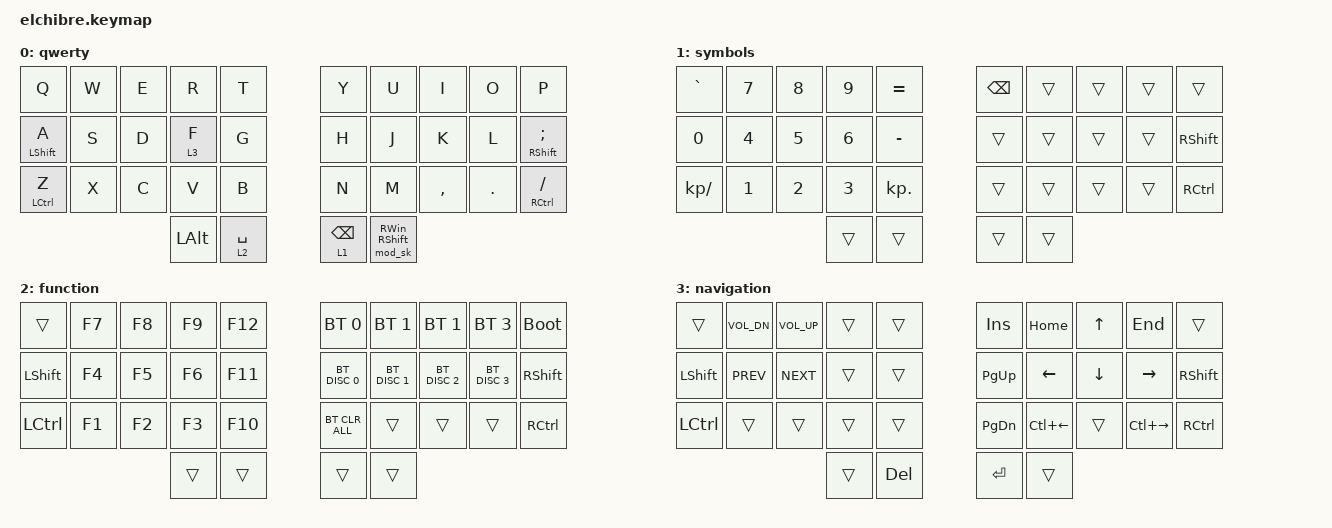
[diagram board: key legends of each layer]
#include <behaviors.dtsi>
#include <dt-bindings/zmk/bt.h>
#include <dt-bindings/zmk/keys.h>
#include <dt-bindings/zmk/outputs.h>
#include "zmk-helpers/helper.h"
#include "zmk-helpers/key-labels/34.h"
#include "behaviors.dtsi"
#include "combos.dtsi"



/ {
    keymap {
        compatible = "zmk,keymap";

        qwerty {
            bindings = <
                &kp  Q        &kp W  &kp E  &kp R    &kp T     &kp Y &kp U &kp I     &kp O      &kp P
                &hml LSHIFT A &kp S  &kp D  &lt 3 F  &kp G     &kp H &kp J &kp K     &kp L      &hmr RSHIFT SEMI
                &hml LCTRL Z  &kp X  &kp C  &kp V    &kp B     &kp N &kp M &kp COMMA &kp PERIOD &hmr RCTRL SLASH
                             &kp LALT         &lt 2 SPACE     &lt 1 BACKSPACE       &mod_sk RWIN RSHIFT 
            >;
        };

        symbols {
            bindings = <
                &kp GRAVE     &kp N7 &kp N8 &kp N9 &kp EQUAL       &kp BACKSPACE &trans &trans &trans &trans  
                &kp N0        &kp N4 &kp N5 &kp N6 &kp MINUS       &trans        &trans &trans &trans &kp RSHIFT
                &kp KP_SLASH  &kp N1 &kp N2 &kp N3 &kp KP_DOT      &trans        &trans &trans &trans &kp RCTRL
                                       &trans          &trans      &trans   &trans
            >;
        };

        function {
            bindings = <
                &trans    &kp F7 &kp F8 &kp F9 &kp F12          &bt BT_SEL 0  &bt BT_SEL 1  &bt BT_SEL 1  &bt BT_SEL 3   &bootloader
		&kp LSHFT &kp F4 &kp F5 &kp F6 &kp F11          &bt BT_DISC 0 &bt BT_DISC 1 &bt BT_DISC 2 &bt BT_DISC 3  &kp RSHIFT
                &kp LCTRL &kp F1 &kp F2 &kp F3 &kp F10          &bt BT_CLR_ALL&trans &trans &trans &kp RCTRL
                              &trans         &trans             &trans         &trans
            >;
        };

        navigation {
            bindings = <
                &trans    &kp C_VOL_DN &kp C_VOL_UP &trans &trans          &kp INS   &kp HOME     &kp UP   &kp END   &trans
                &kp LSHFT &kp C_PREV   &kp C_NEXT   &trans &trans          &kp PG_UP &kp LEFT     &kp DOWN &kp RIGHT &kp RSHFT
                &kp LCTRL &trans       &trans       &trans &trans          &kp PG_DN &kp LC(LEFT) &trans   &kp LC(RIGHT)    &kp RCTRL
                                       &trans              &kp DEL         &kp ENTER    &trans
            >;
        };
    };
};
